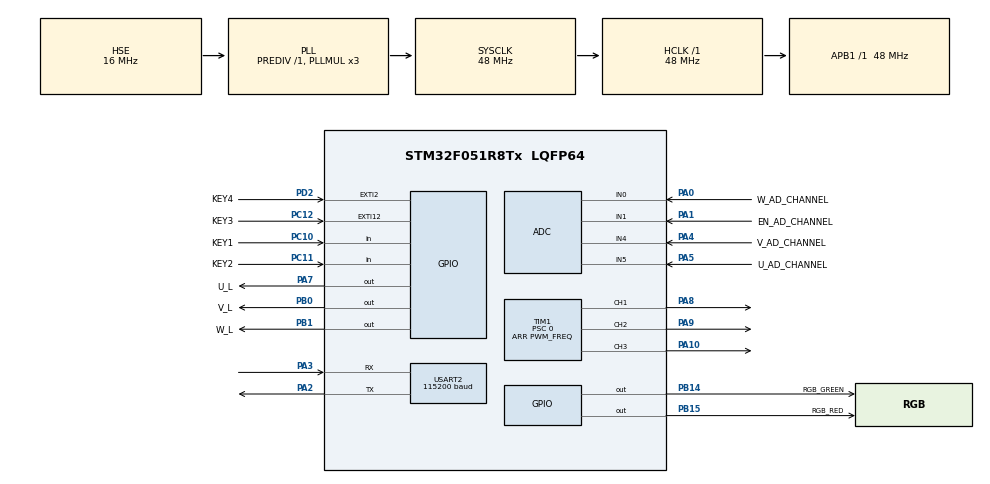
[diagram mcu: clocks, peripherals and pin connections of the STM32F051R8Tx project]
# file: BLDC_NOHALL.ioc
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ADC.ClockPrescaler=ADC_CLOCK_ASYNC_DIV1
ADC.ContinuousConvMode=DISABLE
ADC.DMAContinuousRequests=DISABLE
ADC.DataAlign=ADC_DATAALIGN_RIGHT
ADC.DiscontinuousConvMode=ENABLE
ADC.EOCSelection=ADC_EOC_SEQ_CONV
ADC.ExternalTrigConv=ADC_SOFTWARE_START
ADC.ScanConvMode=ADC_SCAN_DIRECTION_FORWARD
Mcu.Family=STM32F0
Mcu.Name=STM32F051R8Tx
Mcu.Package=LQFP64
Mcu.UserConstants=PWM_FREQ,3200
NVIC.ADC1_COMP_IRQn=true\:3\:0\:true\:false\:true\:true\:true
NVIC.EXTI2_3_IRQn=true\:3\:0\:true\:false\:true\:true\:true
NVIC.EXTI4_15_IRQn=true\:3\:0\:true\:false\:true\:true\:true
NVIC.PVD_IRQn=true\:3\:0\:true\:false\:true\:true\:true
NVIC.TIM14_IRQn=true\:2\:0\:true\:false\:true\:true\:true
NVIC.TIM2_IRQn=true\:2\:0\:true\:false\:true\:true\:true
PA0.GPIO_Label=W_AD_CHANNEL
PA0.Mode=IN0
PA0.Signal=ADC_IN0
PA1.GPIO_Label=EN_AD_CHANNEL
PA1.Mode=IN1
PA1.Signal=ADC_IN1
PA10.Signal=S_TIM1_CH3
PA13.Mode=Serial_Wire
PA13.Signal=SYS_SWDIO
PA14.Mode=Serial_Wire
PA14.Signal=SYS_SWCLK
PA2.Mode=Asynchronous
PA2.Signal=USART2_TX
PA3.Mode=Asynchronous
PA3.Signal=USART2_RX
PA4.GPIO_Label=V_AD_CHANNEL
PA4.Mode=IN4
PA4.Signal=ADC_IN4
PA5.GPIO_Label=U_AD_CHANNEL
PA5.Mode=IN5
PA5.Signal=ADC_IN5
PA7.GPIO_Label=U_L
PA7.Signal=GPIO_Output
PA8.Signal=S_TIM1_CH1
PA9.Signal=S_TIM1_CH2
PB0.GPIO_Label=V_L
PB0.Signal=GPIO_Output
PB1.GPIO_Label=W_L
PB1.Signal=GPIO_Output
PB14.GPIO_Label=RGB_GREEN
PB14.GPIO_Speed=GPIO_SPEED_FREQ_HIGH
PB14.PinState=GPIO_PIN_SET
PB14.Signal=GPIO_Output
PB15.GPIO_Label=RGB_RED
PB15.GPIO_Speed=GPIO_SPEED_FREQ_HIGH
PB15.PinState=GPIO_PIN_SET
PB15.Signal=GPIO_Output
PC10.GPIO_Label=KEY1
PC10.Signal=GPIO_Input
PC11.GPIO_Label=KEY2
PC11.Signal=GPIO_Input
PC12.GPIO_Label=KEY3
PC12.GPIO_PuPd=GPIO_PULLUP
PC12.Signal=GPXTI12
PD2.GPIO_Label=KEY4
PD2.GPIO_PuPd=GPIO_PULLUP
PD2.Signal=GPXTI2
PF0-OSC_IN.Mode=HSE-External-Oscillator
PF0-OSC_IN.Signal=RCC_OSC_IN
PF1-OSC_OUT.Mode=HSE-External-Oscillator
PF1-OSC_OUT.Signal=RCC_OSC_OUT
ProjectManager.HeapSize=0x200
ProjectManager.StackSize=0x400
ProjectManager.TargetToolchain=Makefile
RCC.AHBFreq_Value=48000000
RCC.APB1Freq_Value=48000000
RCC.APB1TimFreq_Value=48000000
RCC.HCLKFreq_Value=48000000
RCC.HSE_VALUE=16000000
RCC.HSI14CalibrationValue=16
RCC.PLLMUL=RCC_PLL_MUL3
RCC.PLLSourceVirtual=RCC_PLLSOURCE_HSE
RCC.SYSCLKFreq_VALUE=48000000
RCC.SYSCLKSource=RCC_SYSCLKSOURCE_PLLCLK
SH.S_TIM1_CH1.0=TIM1_CH1,PWM Generation1 CH1
SH.S_TIM1_CH2.0=TIM1_CH2,PWM Generation2 CH2
SH.S_TIM1_CH3.0=TIM1_CH3,PWM Generation3 CH3
TIM1.AutoReloadPreload=TIM_AUTORELOAD_PRELOAD_ENABLE
TIM1.Channel-PWM\ Generation1\ CH1=TIM_CHANNEL_1
TIM1.Channel-PWM\ Generation2\ CH2=TIM_CHANNEL_2
TIM1.Channel-PWM\ Generation3\ CH3=TIM_CHANNEL_3
TIM1.OCIdleState_1=TIM_OCIDLESTATE_SET
TIM1.OCIdleState_2=TIM_OCIDLESTATE_SET
TIM1.OCIdleState_3=TIM_OCIDLESTATE_SET
TIM1.Period=PWM_FREQ
TIM1.Prescaler=0
TIM1.RepetitionCounter=0
TIM14.AutoReloadPreload=TIM_AUTORELOAD_PRELOAD_ENABLE
TIM14.Period=50
TIM14.Prescaler=47
TIM2.AutoReloadPreload=TIM_AUTORELOAD_PRELOAD_ENABLE
TIM2.Period=0
TIM2.Prescaler=47
USART2.BaudRate=115200
USART2.VirtualMode-Asynchronous=VM_ASYNC
VP_TIM14_VS_ClockSourceINT.Mode=Enable_Timer
VP_TIM1_VS_ClockSourceITR.Mode=TriggerSource_ITR3
VP_TIM2_VS_ClockSourceINT.Mode=Internal
board=custom

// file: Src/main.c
/* USER CODE BEGIN Header */
/**
  ******************************************************************************
  * @file           : main.c
  * @brief          : Main program body
  * @attention
  *
  * <h2><center>&copy; Copyright (c) 2022 STMicroelectronics.
  * All rights reserved.</center></h2>
  *
  * This software component is licensed by ST under BSD 3-Clause license,
  * the "License"; You may not use this file except in compliance with the
  * License. You may obtain a copy of the License at:
  *                        opensource.org/licenses/BSD-3-Clause
  *
  ******************************************************************************
  */
/* USER CODE END Header */
#include "main.h"
#include "adc.h"
#include "tim.h"
#include "usart.h"
#include "gpio.h"

/* USER CODE BEGIN Includes */
#include"stdio.h"
#include "bldc_driver.h"
/* USER CODE END Includes */

/* USER CODE BEGIN PM */
extern TIM_HandleTypeDef htim14;
/* USER CODE END PM */

void SystemClock_Config(void);

int main(void)
{

  /* MCU Configuration--------------------------------------------------------*/

  /* Reset of all peripherals, Initializes the Flash interface and the Systick. */
  HAL_Init();

  /* USER CODE BEGIN Init */

  // uint16_t pwmVal=0;   //PWM占空
  /* USER CODE END Init */

  /* Configure the system clock */
  SystemClock_Config();

  /* Initialize all configured peripherals */
  MX_GPIO_Init();
  MX_TIM1_Init();
  MX_TIM14_Init();
  MX_ADC_Init();
  MX_USART2_UART_Init();
  MX_TIM2_Init();
  /* USER CODE BEGIN 2 */
  HAL_Delay(3000);
  RED_ON;
  GREEN_ON;
  ADC_START_IT;
  // SET_CH1_PWMDUTY(MIN_DUTY);SET_CH2_PWMDUTY(MIN_DUTY);SET_CH3_PWMDUTY(MIN_DUTY);
  // CH1_PWM_START;
  // CH2_PWM_START;
  // CH3_PWM_START;
  /* USER CODE END 2 */

  /* Infinite loop */
  /* USER CODE BEGIN WHILE */
  while (1)
  {
    // GREEN_TOGGLE;
    // HAL_Delay(20);
  //  Motor_ADC_Start_DMA();

    /* USER CODE END WHILE */

  }
}

void SystemClock_Config(void)
{
  RCC_OscInitTypeDef RCC_OscInitStruct = {0};
  RCC_ClkInitTypeDef RCC_ClkInitStruct = {0};

  /** Initializes the RCC Oscillators according to the specified parameters
  * in the RCC_OscInitTypeDef structure.
  */
  RCC_OscInitStruct.OscillatorType = RCC_OSCILLATORTYPE_HSI14|RCC_OSCILLATORTYPE_HSE;
  RCC_OscInitStruct.HSEState = RCC_HSE_ON;
  RCC_OscInitStruct.HSI14State = RCC_HSI14_ON;
  RCC_OscInitStruct.HSI14CalibrationValue = 16;
  RCC_OscInitStruct.PLL.PLLState = RCC_PLL_ON;
  RCC_OscInitStruct.PLL.PLLSource = RCC_PLLSOURCE_HSE;
  RCC_OscInitStruct.PLL.PLLMUL = RCC_PLL_MUL3;
  RCC_OscInitStruct.PLL.PREDIV = RCC_PREDIV_DIV1;
  if (HAL_RCC_OscConfig(&RCC_OscInitStruct) != HAL_OK)
  {
    Error_Handler();
  }
  /** Initializes the CPU, AHB and APB buses clocks
  */
  RCC_ClkInitStruct.ClockType = RCC_CLOCKTYPE_HCLK|RCC_CLOCKTYPE_SYSCLK
                              |RCC_CLOCKTYPE_PCLK1;
  RCC_ClkInitStruct.SYSCLKSource = RCC_SYSCLKSOURCE_PLLCLK;
  RCC_ClkInitStruct.AHBCLKDivider = RCC_SYSCLK_DIV1;
  RCC_ClkInitStruct.APB1CLKDivider = RCC_HCLK_DIV1;

  if (HAL_RCC_ClockConfig(&RCC_ClkInitStruct, FLASH_LATENCY_1) != HAL_OK)
  {
    Error_Handler();
  }
}

void Error_Handler(void)
{
  __disable_irq();
  while (1)
  {
  }
}

/************************ (C) COPYRIGHT STMicroelectronics *****END OF FILE****/
